# CY8C5588AXI_060ES1 register map
File version: 0.1
CY8C55
Registers are 8-bit, read-write, no defined reset value unless marked. A register's access mark holds for its fields unless they carry their own. Offsets are from the block's base; lines under a group give offsets from that group; [hi:lo] are bit positions; {n}, {i} and the like mark numbered series; 'fields as' and 'values as' point back to an identical list; <NAME> marks a mode.

## Memory map
0x400043AA ADCSharp size 0x17E0
0x40006423 UART_XBee size 0x43 — UART
0x40006427 UART_Asser size 0x13E — UART
0x40006476 PWM_LanceurGauche size 0x122
0x40006504 Timer_Fin size 0x92
0x40006528 PWM_LanceurDroit size 0x72
0x4000652A PWM_Queue size 0x72

## PWM_Queue
Base 0x4000652A
0x00 PWM_Queue_COMPARE_Reg 16-bit — UDB.D0 - Assigned Compare Value
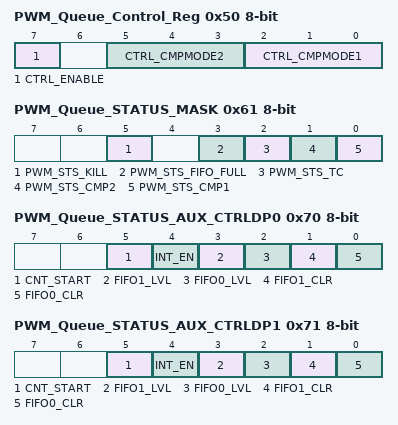
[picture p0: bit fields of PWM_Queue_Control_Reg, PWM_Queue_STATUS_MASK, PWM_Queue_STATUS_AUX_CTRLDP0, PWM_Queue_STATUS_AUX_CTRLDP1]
0x50 PWM_Queue_Control_Reg — UDB Control Register - Assigned Control Register Value
  [7] CTRL_ENABLE — Enable the PWM
  [5:3] CTRL_CMPMODE2 — Compare mode 2
  [2:0] CTRL_CMPMODE1 — Compare mode 1
0x61 PWM_Queue_STATUS_MASK — UDB Status bits Interrupt Mask Enable Register
  [5] PWM_STS_KILL ro — Enables the Interrupt on Kill
  [3] PWM_STS_FIFO_FULL ro — FIFO Full Status Mask
  [2] PWM_STS_TC ro — Enables the Interrupt on Terminal Count
  [1] PWM_STS_CMP2 ro — Enables the Interrupt on Compare 2
  [0] PWM_STS_CMP1 ro — Enables the Interrupt on Compare 1
0x70 PWM_Queue_STATUS_AUX_CTRLDP0 — UDB Auxilliary Control Register
  [5] CNT_START — FIFO0 clear
    0=E_CNT_START0 (Disable counter); 1=E_CNT_START1 (Enable counter)
  [4] INT_EN
    0=E_INT_EN0 (Interrupt disabled); 1=E_INT_EN1 (Interrupt enabled)
  [3] FIFO1_LVL — FIFO level
    0=E_FIFO_LVL_0 (FIFO LVL: input mode: FIFO not full; output mode: FIFO not empty); 1=E_FIFO_LVL_1 (FIFO LVL: input mode: FIFO at least 1/2 empty; output mode: FIFO at least 1/2 full)
  [2] FIFO0_LVL — FIFO level
    values as FIFO1_LVL
  [1] FIFO1_CLR — FIFO1 clear
    0=E_FIFO_CLR_0 (Normal FIFO operation); 1=E_FIFO_CLR_1 (Clear FIFO state)
  [0] FIFO0_CLR — FIFO0 clear
    values as FIFO1_CLR
0x71 PWM_Queue_STATUS_AUX_CTRLDP1 — UDB Auxilliary Control Register
  fields as PWM_Queue_STATUS_AUX_CTRLDP0

## PWM_LanceurDroit
Base 0x40006528
Registers as PWM_Queue (with PWM_Queue read as PWM_LanceurDroit), without PWM_Queue_Control_Reg; these are added or differ:
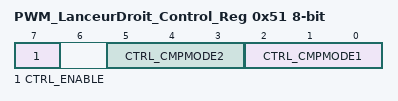
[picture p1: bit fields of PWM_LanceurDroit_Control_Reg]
0x51 PWM_LanceurDroit_Control_Reg — UDB Control Register - Assigned Control Register Value
  [7] CTRL_ENABLE — Enable the PWM
  [5:3] CTRL_CMPMODE2 — Compare mode 2
  [2:0] CTRL_CMPMODE1 — Compare mode 1

## PWM_LanceurGauche
Base 0x40006476
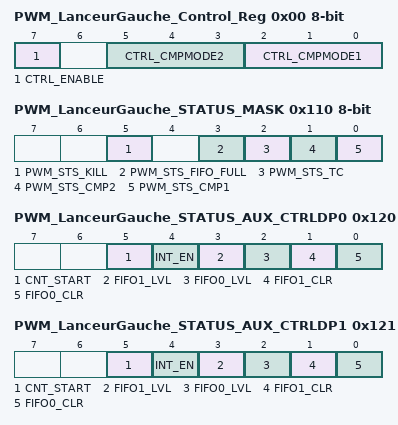
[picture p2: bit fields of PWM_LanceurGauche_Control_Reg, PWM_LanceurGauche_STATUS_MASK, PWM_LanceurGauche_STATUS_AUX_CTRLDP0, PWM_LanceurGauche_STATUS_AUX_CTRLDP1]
0x00 PWM_LanceurGauche_Control_Reg — UDB Control Register - Assigned Control Register Value
  [7] CTRL_ENABLE — Enable the PWM
  [5:3] CTRL_CMPMODE2 — Compare mode 2
  [2:0] CTRL_CMPMODE1 — Compare mode 1
0xB0 PWM_LanceurGauche_COMPARE_Reg 16-bit — UDB.D0 - Assigned Compare Value
0x110 PWM_LanceurGauche_STATUS_MASK — UDB Status bits Interrupt Mask Enable Register
  [5] PWM_STS_KILL ro — Enables the Interrupt on Kill
  [3] PWM_STS_FIFO_FULL ro — FIFO Full Status Mask
  [2] PWM_STS_TC ro — Enables the Interrupt on Terminal Count
  [1] PWM_STS_CMP2 ro — Enables the Interrupt on Compare 2
  [0] PWM_STS_CMP1 ro — Enables the Interrupt on Compare 1
0x120 PWM_LanceurGauche_STATUS_AUX_CTRLDP0 — UDB Auxilliary Control Register
  [5] CNT_START — FIFO0 clear
    0=E_CNT_START0 (Disable counter); 1=E_CNT_START1 (Enable counter)
  [4] INT_EN
    0=E_INT_EN0 (Interrupt disabled); 1=E_INT_EN1 (Interrupt enabled)
  [3] FIFO1_LVL — FIFO level
    0=E_FIFO_LVL_0 (FIFO LVL: input mode: FIFO not full; output mode: FIFO not empty); 1=E_FIFO_LVL_1 (FIFO LVL: input mode: FIFO at least 1/2 empty; output mode: FIFO at least 1/2 full)
  [2] FIFO0_LVL — FIFO level
    values as FIFO1_LVL
  [1] FIFO1_CLR — FIFO1 clear
    0=E_FIFO_CLR_0 (Normal FIFO operation); 1=E_FIFO_CLR_1 (Clear FIFO state)
  [0] FIFO0_CLR — FIFO0 clear
    values as FIFO1_CLR
0x121 PWM_LanceurGauche_STATUS_AUX_CTRLDP1 — UDB Auxilliary Control Register
  fields as PWM_LanceurGauche_STATUS_AUX_CTRLDP0
